# gpio register map
Vendor: Texas Instruments
Peripheral module from a debugger description file (folder tm4e129xnczad).
Registers are 32-bit, access not given, no defined reset value unless marked. A register's access mark holds for its fields unless they carry their own. Offsets are as the file gives them; lines under a group give offsets from that group; [hi:lo] are bit positions; {n}, {i} and the like mark numbered series; 'fields as' and 'values as' point back to an identical list; <NAME> marks a mode.

## GPIO_PORTA_AHB — GPIO register offsets
0x3FC GPIO_DATA
0x400 GPIO_DIR — GPIO Direction
0x404 GPIO_IS — GPIO Interrupt Sense
0x408 GPIO_IBE — GPIO Interrupt Both Edges
0x40C GPIO_IEV — GPIO Interrupt Event
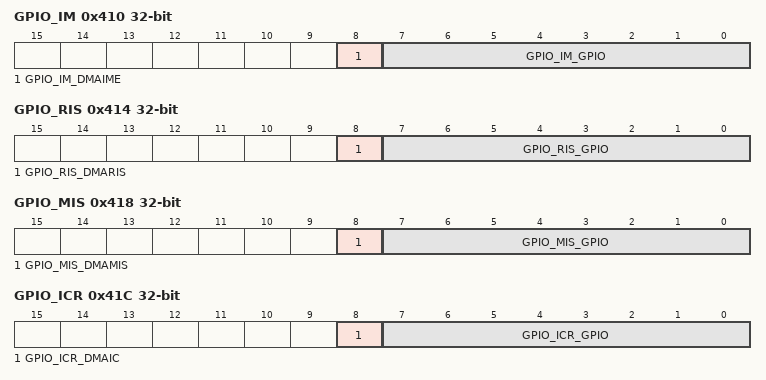
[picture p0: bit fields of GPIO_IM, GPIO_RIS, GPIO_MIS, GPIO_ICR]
0x410 GPIO_IM rw — GPIO Interrupt Mask
  [8] GPIO_IM_DMAIME — GPIO uDMA Done Interrupt Mask Enable
  [7:0] GPIO_IM_GPIO — GPIO Interrupt Mask Enable
0x414 GPIO_RIS ro — GPIO Raw Interrupt Status
  [8] GPIO_RIS_DMARIS — GPIO uDMA Done Interrupt Raw Status
  [7:0] GPIO_RIS_GPIO — GPIO Interrupt Raw Status
0x418 GPIO_MIS ro — GPIO Masked Interrupt Status
  [8] GPIO_MIS_DMAMIS — GPIO uDMA Done Masked Interrupt Status
  [7:0] GPIO_MIS_GPIO — GPIO Masked Interrupt Status
0x41C GPIO_ICR wo — GPIO Interrupt Clear
  [8] GPIO_ICR_DMAIC — GPIO uDMA Interrupt Clear
  [7:0] GPIO_ICR_GPIO — GPIO Interrupt Clear
0x420 GPIO_AFSEL — GPIO Alternate Function Select
0x500 GPIO_DR2R — GPIO 2-mA Drive Select
0x504 GPIO_DR4R — GPIO 4-mA Drive Select
0x508 GPIO_DR8R — GPIO 8-mA Drive Select
0x50C GPIO_ODR — GPIO Open Drain Select
0x510 GPIO_PUR — GPIO Pull-Up Select
0x514 GPIO_PDR — GPIO Pull-Down Select
0x518 GPIO_SLR — GPIO Slew Rate Control Select
0x51C GPIO_DEN — GPIO Digital Enable
0x520 GPIO_LOCK rw
  [31:0] GPIO_LOCK
    0=GPIO_LOCK_UNLOCKED (The GPIOCR register is unlocked and may be modified); 1=GPIO_LOCK_LOCKED (The GPIOCR register is locked and may not be modified); 0x4C4F434B=GPIO_LOCK_KEY (Unlocks the GPIO_CR register)
0x524 GPIO_CR — GPIO Commit
0x528 GPIO_AMSEL — GPIO Analog Mode Select
0x52C GPIO_PCTL — GPIO Port Control
0x530 GPIO_ADCCTL — GPIO ADC Control
0x534 GPIO_DMACTL — GPIO DMA Control
0x538 GPIO_SI rw — GPIO Select Interrupt
  [0] GPIO_SI_SUM — Summary Interrupt
0x53C GPIO_DR12R rw — GPIO 12-mA Drive Select
  [7:0] GPIO_DR12R_DRV12 — Output Pad 12-mA Drive Enable
    1=GPIO_DR12R_DRV12_12MA (The corresponding GPIO pin has 12-mA drive. This encoding is only valid if the GPIOPP EDE bit is set and the appropriate GPIOPC EDM bit field is programmed to 0x3)
0x540 GPIO_WAKEPEN rw — GPIO Wake Pin Enable
  [4] GPIO_WAKEPEN_WAKEP4 — P[4] Wake Enable
0x544 GPIO_WAKELVL rw — GPIO Wake Level
  [4] GPIO_WAKELVL_WAKELVL4 — P[4] Wake Level
0x548 GPIO_WAKESTAT ro — GPIO Wake Status
  [4] GPIO_WAKESTAT_STAT4 — P[4] Wake Status
0xFC0 GPIO_PP ro — GPIO Peripheral Property
  [0] GPIO_PP_EDE — Extended Drive Enable
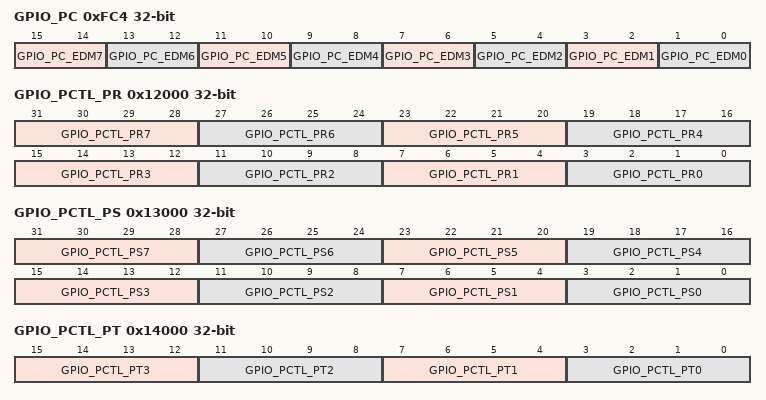
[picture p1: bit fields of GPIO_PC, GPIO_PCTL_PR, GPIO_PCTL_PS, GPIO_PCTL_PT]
0xFC4 GPIO_PC rw — GPIO Peripheral Configuration
  [2n+1:2n] GPIO_PC_EDM{n} (n=1..7) — Extended Drive Mode Bit {n}
  [1:0] GPIO_PC_EDM0 — Extended Drive Mode Bit 0
    0=GPIO_PC_EDM0_DISABLE (Drive values of 2, 4 and 8 mA are maintained. GPIO n Drive Select (GPIODRnR) registers function as normal); 1=GPIO_PC_EDM0_6MA (An additional 6 mA option is provided); 3=GPIO_PC_EDM0_PLUS2MA (A 2 mA driver is always enabled; setting the corresponding GPIODR4R register bit adds 2 mA and setting the corresponding GPIODR8R of GPIODR12R register bit adds an additional 4 mA)
0x12000 GPIO_PCTL_PR rw — PR4
  [31:28] GPIO_PCTL_PR7 — PR7 Mask
    2=GPIO_PCTL_PR7_I2C4SDA (I2C4SDA on PR7); 3=GPIO_PCTL_PR7_T1CCP1 (T1CCP1 on PR7); 4=GPIO_PCTL_PR7_KBCOUT15 (KBCOUT15 on PR7); 6=GPIO_PCTL_PR7_M0PWM7 (M0PWM7 on PR7); 14=GPIO_PCTL_PR7_EN0TXEN (EN0TXEN on PR7); 15=GPIO_PCTL_PR7_LCDDATA05 (LCDDATA05 on PR7)
  [27:24] GPIO_PCTL_PR6 — PR6 Mask
    1=GPIO_PCTL_PR6_U1TX (U1TX on PR6); 2=GPIO_PCTL_PR6_I2C4SCL (I2C4SCL on PR6); 3=GPIO_PCTL_PR6_T1CCP0 (T1CCP0 on PR6); 4=GPIO_PCTL_PR6_KBCOUT14 (KBCOUT14 on PR6); 5=GPIO_PCTL_PR6_LPC0COMYTX (LPC0COMYTX on PR6); 6=GPIO_PCTL_PR6_M0PWM6 (M0PWM6 on PR6); 15=GPIO_PCTL_PR6_LCDDATA04 (LCDDATA04 on PR6)
  [23:20] GPIO_PCTL_PR5 — PR5 Mask
    1=GPIO_PCTL_PR5_U1RX (U1RX on PR5); 2=GPIO_PCTL_PR5_I2C3SDA (I2C3SDA on PR5); 3=GPIO_PCTL_PR5_T0CCP1 (T0CCP1 on PR5); 4=GPIO_PCTL_PR5_KBCOUT13 (KBCOUT13 on PR5); 5=GPIO_PCTL_PR5_LPC0COMYRX (LPC0COMYRX on PR5); 6=GPIO_PCTL_PR5_M0PWM5 (M0PWM5 on PR5); 15=GPIO_PCTL_PR5_LCDDATA01 (LCDDATA01 on PR5)
  [19:16] GPIO_PCTL_PR4 — PR4 Mask
    2=GPIO_PCTL_PR4_I2C3SCL (I2C3SCL on PR4); 3=GPIO_PCTL_PR4_T0CCP0 (T0CCP0 on PR4); 4=GPIO_PCTL_PR4_KBCOUT12 (KBCOUT12 on PR4); 6=GPIO_PCTL_PR4_M0PWM4 (M0PWM4 on PR4); 15=GPIO_PCTL_PR4_LCDDATA00 (LCDDATA00 on PR4)
  [15:12] GPIO_PCTL_PR3 — PR3 Mask
    2=GPIO_PCTL_PR3_I2C2SDA (I2C2SDA on PR3); 4=GPIO_PCTL_PR3_KBCOUT11 (KBCOUT11 on PR3); 6=GPIO_PCTL_PR3_M0PWM3 (M0PWM3 on PR3); 15=GPIO_PCTL_PR3_LCDDATA03 (LCDDATA03 on PR3)
  [11:8] GPIO_PCTL_PR2 — PR2 Mask
    2=GPIO_PCTL_PR2_I2C2SCL (I2C2SCL on PR2); 4=GPIO_PCTL_PR2_KBCOUT10 (KBCOUT10 on PR2); 6=GPIO_PCTL_PR2_M0PWM2 (M0PWM2 on PR2); 15=GPIO_PCTL_PR2_LCDLP (LCDLP on PR2)
  [7:4] GPIO_PCTL_PR1 — PR1 Mask
    1=GPIO_PCTL_PR1_U4RX (U4RX on PR1); 2=GPIO_PCTL_PR1_I2C1SDA (I2C1SDA on PR1); 4=GPIO_PCTL_PR1_KBCOUT09 (KBCOUT09 on PR1); 6=GPIO_PCTL_PR1_M0PWM1 (M0PWM1 on PR1); 15=GPIO_PCTL_PR1_LCDFP (LCDFP on PR1)
  [3:0] GPIO_PCTL_PR0 — PR0 Mask
    1=GPIO_PCTL_PR0_U4TX (U4TX on PR0); 2=GPIO_PCTL_PR0_I2C1SCL (I2C1SCL on PR0); 4=GPIO_PCTL_PR0_KBCOUT08 (KBCOUT08 on PR0); 6=GPIO_PCTL_PR0_M0PWM0 (M0PWM0 on PR0); 15=GPIO_PCTL_PR0_LCDCP (LCDCP on PR0)
0x13000 GPIO_PCTL_PS rw — PS1
  [31:28] GPIO_PCTL_PS7 — PS7 Mask
    3=GPIO_PCTL_PS7_T5CCP1 (T5CCP1 on PS7); 4=GPIO_PCTL_PS7_KBCIN04 (KBCIN04 on PS7); 14=GPIO_PCTL_PS7_EN0RXDV (EN0RXDV on PS7); 15=GPIO_PCTL_PS7_LCDDATA09 (LCDDATA09 on PS7)
  [27:24] GPIO_PCTL_PS6 — PS6 Mask
    3=GPIO_PCTL_PS6_T5CCP0 (T5CCP0 on PS6); 4=GPIO_PCTL_PS6_KBCIN05 (KBCIN05 on PS6); 6=GPIO_PCTL_PS6_IDX0 (IDX0 on PS6); 14=GPIO_PCTL_PS6_EN0RXER (EN0RXER on PS6); 15=GPIO_PCTL_PS6_LCDDATA08 (LCDDATA08 on PS6)
  [23:20] GPIO_PCTL_PS5 — PS5 Mask
    3=GPIO_PCTL_PS5_T4CCP1 (T4CCP1 on PS5); 4=GPIO_PCTL_PS5_KBCIN06 (KBCIN06 on PS5); 6=GPIO_PCTL_PS5_PHB0 (PHB0 on PS5); 14=GPIO_PCTL_PS5_EN0TXD1 (EN0TXD1 on PS5); 15=GPIO_PCTL_PS5_LCDDATA07 (LCDDATA07 on PS5)
  [19:16] GPIO_PCTL_PS4 — PS4 Mask
    3=GPIO_PCTL_PS4_T4CCP0 (T4CCP0 on PS4); 4=GPIO_PCTL_PS4_KBCIN07 (KBCIN07 on PS4); 6=GPIO_PCTL_PS4_PHA0 (PHA0 on PS4); 14=GPIO_PCTL_PS4_EN0TXD0 (EN0TXD0 on PS4); 15=GPIO_PCTL_PS4_LCDDATA06 (LCDDATA06 on PS4)
  [15:12] GPIO_PCTL_PS3 — PS3 Mask
    3=GPIO_PCTL_PS3_T3CCP1 (T3CCP1 on PS3); 4=GPIO_PCTL_PS3_KBCOUT19 (KBCOUT19 on PS3); 6=GPIO_PCTL_PS3_M0FAULT3 (M0FAULT3 on PS3); 15=GPIO_PCTL_PS3_LCDDATA23 (LCDDATA23 on PS3)
  [11:8] GPIO_PCTL_PS2 — PS2 Mask
    1=GPIO_PCTL_PS2_U1DSR (U1DSR on PS2); 3=GPIO_PCTL_PS2_T3CCP0 (T3CCP0 on PS2); 4=GPIO_PCTL_PS2_KBCOUT18 (KBCOUT18 on PS2); 6=GPIO_PCTL_PS2_M0FAULT2 (M0FAULT2 on PS2); 15=GPIO_PCTL_PS2_LCDDATA22 (LCDDATA22 on PS2)
  [7:4] GPIO_PCTL_PS1 — PS1 Mask
    3=GPIO_PCTL_PS1_T2CCP1 (T2CCP1 on PS1); 4=GPIO_PCTL_PS1_KBCOUT17 (KBCOUT17 on PS1); 6=GPIO_PCTL_PS1_M0FAULT1 (M0FAULT1 on PS1); 13=GPIO_PCTL_PS1_LPC0RESET_N (LPC0RESET_N on PS1); 15=GPIO_PCTL_PS1_LCDDATA21 (LCDDATA21 on PS1)
  [3:0] GPIO_PCTL_PS0 — PS0 Mask
    3=GPIO_PCTL_PS0_T2CCP0 (T2CCP0 on PS0); 4=GPIO_PCTL_PS0_KBCOUT16 (KBCOUT16 on PS0); 6=GPIO_PCTL_PS0_M0FAULT0 (M0FAULT0 on PS0); 13=GPIO_PCTL_PS0_LPC0A20 (LPC0A20 on PS0); 15=GPIO_PCTL_PS0_LCDDATA20 (LCDDATA20 on PS0)
0x14000 GPIO_PCTL_PT rw — PT2
  [15:12] GPIO_PCTL_PT3 — PT3 Mask
    3=GPIO_PCTL_PT3_T7CCP1 (T7CCP1 on PT3); 4=GPIO_PCTL_PT3_KBCIN00 (KBCIN00 on PT3); 7=GPIO_PCTL_PT3_CAN1TX (CAN1TX on PT3); 15=GPIO_PCTL_PT3_LCDDATA19 (LCDDATA19 on PT3)
  [11:8] GPIO_PCTL_PT2 — PT2 Mask
    3=GPIO_PCTL_PT2_T7CCP0 (T7CCP0 on PT2); 4=GPIO_PCTL_PT2_KBCIN01 (KBCIN01 on PT2); 7=GPIO_PCTL_PT2_CAN1RX (CAN1RX on PT2); 15=GPIO_PCTL_PT2_LCDDATA18 (LCDDATA18 on PT2)
  [7:4] GPIO_PCTL_PT1 — PT1 Mask
    3=GPIO_PCTL_PT1_T6CCP1 (T6CCP1 on PT1); 4=GPIO_PCTL_PT1_KBCIN02 (KBCIN02 on PT1); 7=GPIO_PCTL_PT1_CAN0TX (CAN0TX on PT1); 14=GPIO_PCTL_PT1_EN0RXD1 (EN0RXD1 on PT1); 15=GPIO_PCTL_PT1_LCDDATA11 (LCDDATA11 on PT1)
  [3:0] GPIO_PCTL_PT0 — PT0 Mask
    3=GPIO_PCTL_PT0_T6CCP0 (T6CCP0 on PT0); 4=GPIO_PCTL_PT0_KBCIN03 (KBCIN03 on PT0); 7=GPIO_PCTL_PT0_CAN0RX (CAN0RX on PT0); 14=GPIO_PCTL_PT0_EN0RXD0 (EN0RXD0 on PT0); 15=GPIO_PCTL_PT0_LCDDATA10 (LCDDATA10 on PT0)
